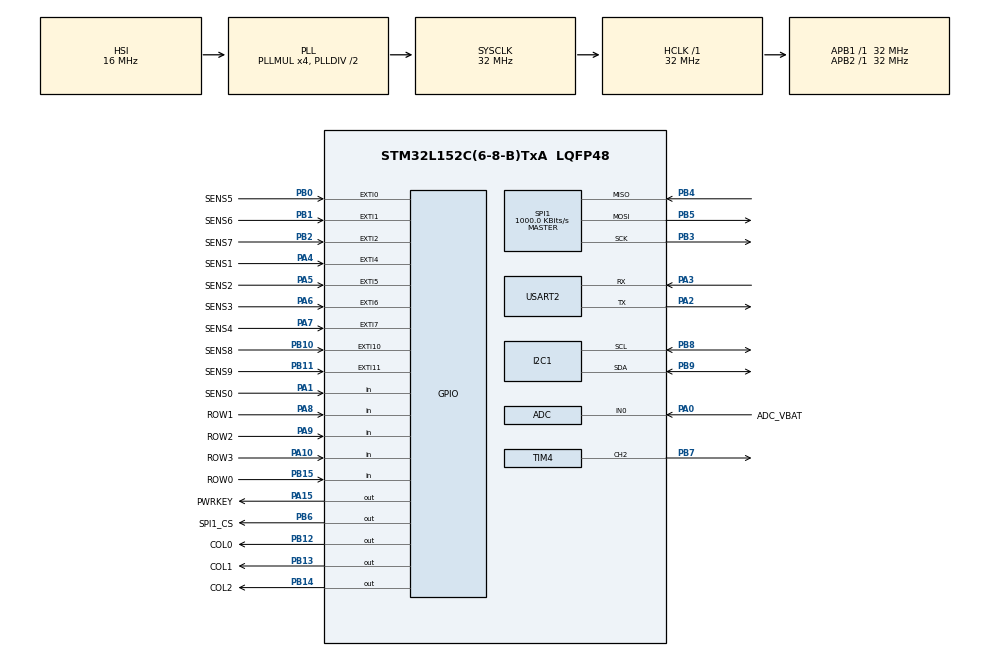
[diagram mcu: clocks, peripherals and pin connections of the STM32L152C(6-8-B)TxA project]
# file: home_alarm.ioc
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ADC.Channel-1\#ChannelRegularConversion=ADC_CHANNEL_0
ADC.NbrOfConversionFlag=1
ADC.Rank-1\#ChannelRegularConversion=1
ADC.SamplingTime-1\#ChannelRegularConversion=ADC_SAMPLETIME_4CYCLES
Dma.Request0=USART2_RX
Dma.USART2_RX.0.Direction=DMA_PERIPH_TO_MEMORY
Dma.USART2_RX.0.Instance=DMA1_Channel6
Dma.USART2_RX.0.MemDataAlignment=DMA_MDATAALIGN_BYTE
Dma.USART2_RX.0.MemInc=DMA_MINC_DISABLE
Dma.USART2_RX.0.Mode=DMA_CIRCULAR
Dma.USART2_RX.0.PeriphDataAlignment=DMA_PDATAALIGN_BYTE
Dma.USART2_RX.0.PeriphInc=DMA_PINC_DISABLE
Dma.USART2_RX.0.Priority=DMA_PRIORITY_VERY_HIGH
Mcu.Family=STM32L1
Mcu.Name=STM32L152C(6-8-B)TxA
Mcu.Package=LQFP48
NVIC.DMA1_Channel6_IRQn=true\:6\:0\:true\:false\:true\:false\:true\:true
NVIC.EXTI0_IRQn=true\:0\:0\:false\:false\:true\:true\:true\:true
NVIC.EXTI15_10_IRQn=true\:0\:0\:false\:false\:true\:true\:true\:true
NVIC.EXTI1_IRQn=true\:0\:0\:false\:false\:true\:true\:true\:true
NVIC.EXTI2_IRQn=true\:0\:0\:false\:false\:true\:true\:true\:true
NVIC.EXTI4_IRQn=true\:0\:0\:false\:false\:true\:true\:true\:true
NVIC.EXTI9_5_IRQn=true\:0\:0\:false\:false\:true\:true\:true\:true
NVIC.PriorityGroup=NVIC_PRIORITYGROUP_4
NVIC.TIM6_IRQn=true\:15\:0\:false\:false\:true\:false\:true\:true
NVIC.TimeBase=TIM6_IRQn
NVIC.TimeBaseIP=TIM6
PA0-WKUP1.GPIO_Label=ADC_VBAT
PA0-WKUP1.Mode=IN0
PA0-WKUP1.Signal=ADC_IN0
PA1.GPIO_Label=SENS0
PA1.Signal=GPIO_Input
PA10.GPIO_Label=ROW3
PA10.GPIO_PuPd=GPIO_PULLUP
PA10.Signal=GPIO_Input
PA13.Mode=Serial_Wire
PA13.Signal=SYS_JTMS-SWDIO
PA14.Mode=Serial_Wire
PA14.Signal=SYS_JTCK-SWCLK
PA15.GPIO_Label=PWRKEY
PA15.Signal=GPIO_Output
PA2.Mode=Asynchronous
PA2.Signal=USART2_TX
PA3.Mode=Asynchronous
PA3.Signal=USART2_RX
PA4.GPIO_Label=SENS1
PA4.Signal=GPXTI4
PA5.GPIO_Label=SENS2
PA5.Signal=GPXTI5
PA6.GPIO_Label=SENS3
PA6.Signal=GPXTI6
PA7.GPIO_Label=SENS4
PA7.Signal=GPXTI7
PA8.GPIO_Label=ROW1
PA8.GPIO_PuPd=GPIO_PULLUP
PA8.Signal=GPIO_Input
PA9.GPIO_Label=ROW2
PA9.GPIO_PuPd=GPIO_PULLUP
PA9.Signal=GPIO_Input
PB0.GPIO_Label=SENS5
PB0.Signal=GPXTI0
PB1.GPIO_Label=SENS6
PB1.Signal=GPXTI1
PB10.GPIO_Label=SENS8
PB10.Signal=GPXTI10
PB11.GPIO_Label=SENS9
PB11.Signal=GPXTI11
PB12.GPIO_Label=COL0
PB12.GPIO_Speed=GPIO_SPEED_FREQ_VERY_HIGH
PB12.Signal=GPIO_Output
PB13.GPIO_Label=COL1
PB13.GPIO_Speed=GPIO_SPEED_FREQ_VERY_HIGH
PB13.Signal=GPIO_Output
PB14.GPIO_Label=COL2
PB14.GPIO_Speed=GPIO_SPEED_FREQ_VERY_HIGH
PB14.Signal=GPIO_Output
PB15.GPIO_Label=ROW0
PB15.GPIO_PuPd=GPIO_PULLUP
PB15.Signal=GPIO_Input
PB2.GPIO_Label=SENS7
PB2.Signal=GPXTI2
PB3.Mode=Full_Duplex_Master
PB3.Signal=SPI1_SCK
PB4.Mode=Full_Duplex_Master
PB4.Signal=SPI1_MISO
PB5.Mode=Full_Duplex_Master
PB5.Signal=SPI1_MOSI
PB6.GPIO_Label=SPI1_CS
PB6.Signal=GPIO_Output
PB7.Signal=S_TIM4_CH2
PB8.Mode=I2C
PB8.Signal=I2C1_SCL
PB9.Mode=I2C
PB9.Signal=I2C1_SDA
ProjectManager.HeapSize=0x200
ProjectManager.StackSize=0x400
ProjectManager.TargetToolchain=STM32CubeIDE
RCC.48MHZClocksFreq_Value=32000000
RCC.AHBFreq_Value=32000000
RCC.APB1Freq_Value=32000000
RCC.APB1TimFreq_Value=32000000
RCC.APB2Freq_Value=32000000
RCC.APB2TimFreq_Value=32000000
RCC.HCLKFreq_Value=32000000
RCC.HSE_VALUE=24000000
RCC.HSI_VALUE=16000000
RCC.LSE_VALUE=32768
RCC.MSI_VALUE=2097000
RCC.PLLMUL=RCC_PLL_MUL4
RCC.SYSCLKFreq_VALUE=32000000
RCC.SYSCLKSource=RCC_SYSCLKSOURCE_PLLCLK
RCC.VCOOutputFreq_Value=64000000
SH.S_TIM4_CH2.0=TIM4_CH2,PWM Generation2 CH2
SPI1.BaudRatePrescaler=SPI_BAUDRATEPRESCALER_32
SPI1.CLKPhase=SPI_PHASE_1EDGE
SPI1.CLKPolarity=SPI_POLARITY_LOW
SPI1.CalculateBaudRate=1000.0 KBits/s
SPI1.Direction=SPI_DIRECTION_2LINES
SPI1.Mode=SPI_MODE_MASTER
SPI1.VirtualType=VM_MASTER
TIM4.AutoReloadPreload=TIM_AUTORELOAD_PRELOAD_ENABLE
TIM4.Channel-PWM\ Generation2\ CH2=TIM_CHANNEL_2
TIM4.Period=137
TIM4.Prescaler=32
USART2.VirtualMode=VM_ASYNC
VP_CRC_VS_CRC.Mode=CRC_Activate
VP_SYS_VS_tim6.Mode=TIM6
board=custom

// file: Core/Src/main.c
/* USER CODE BEGIN Header */
/**
  ******************************************************************************
  * @file           : main.c
  * @brief          : Main program body
  ******************************************************************************
  * @attention
  *
  * Copyright (c) 2022 STMicroelectronics.
  * All rights reserved.
  *
  * This software is licensed under terms that can be found in the LICENSE file
  * in the root directory of this software component.
  * If no LICENSE file comes with this software, it is provided AS-IS.
  *
  ******************************************************************************
  */
/* USER CODE END Header */
#include "main.h"
#include "adc.h"
#include "crc.h"
#include "dma.h"
#include "i2c.h"
#include "spi.h"
#include "tim.h"
#include "usart.h"
#include "gpio.h"

/* USER CODE BEGIN Includes */
#include "app.h"
/* USER CODE END Includes */

void SystemClock_Config(void);

int main(void)
{

  /* MCU Configuration--------------------------------------------------------*/

  /* Reset of all peripherals, Initializes the Flash interface and the Systick. */
  HAL_Init();

  /* Configure the system clock */
  SystemClock_Config();

  /* Initialize all configured peripherals */
  MX_GPIO_Init();
  MX_DMA_Init();
  MX_ADC_Init();
  MX_TIM4_Init();
  MX_USART2_UART_Init();
  MX_I2C1_Init();
  MX_SPI1_Init();
  MX_CRC_Init();
  /* USER CODE BEGIN 2 */
  app_main();
  /* USER CODE END 2 */

  /* Infinite loop */
  while (1)
  {

    /* USER CODE BEGIN 3 */
	  __NOP();
  }
  /* USER CODE END 3 */
}

void SystemClock_Config(void)
{
  RCC_OscInitTypeDef RCC_OscInitStruct = {0};
  RCC_ClkInitTypeDef RCC_ClkInitStruct = {0};

  /** Configure the main internal regulator output voltage
  */
  __HAL_PWR_VOLTAGESCALING_CONFIG(PWR_REGULATOR_VOLTAGE_SCALE1);

  /** Initializes the RCC Oscillators according to the specified parameters
  * in the RCC_OscInitTypeDef structure.
  */
  RCC_OscInitStruct.OscillatorType = RCC_OSCILLATORTYPE_HSI;
  RCC_OscInitStruct.HSIState = RCC_HSI_ON;
  RCC_OscInitStruct.HSICalibrationValue = RCC_HSICALIBRATION_DEFAULT;
  RCC_OscInitStruct.PLL.PLLState = RCC_PLL_ON;
  RCC_OscInitStruct.PLL.PLLSource = RCC_PLLSOURCE_HSI;
  RCC_OscInitStruct.PLL.PLLMUL = RCC_PLL_MUL4;
  RCC_OscInitStruct.PLL.PLLDIV = RCC_PLL_DIV2;
  if (HAL_RCC_OscConfig(&RCC_OscInitStruct) != HAL_OK)
  {
    Error_Handler();
  }

  /** Initializes the CPU, AHB and APB buses clocks
  */
  RCC_ClkInitStruct.ClockType = RCC_CLOCKTYPE_HCLK|RCC_CLOCKTYPE_SYSCLK
                              |RCC_CLOCKTYPE_PCLK1|RCC_CLOCKTYPE_PCLK2;
  RCC_ClkInitStruct.SYSCLKSource = RCC_SYSCLKSOURCE_PLLCLK;
  RCC_ClkInitStruct.AHBCLKDivider = RCC_SYSCLK_DIV1;
  RCC_ClkInitStruct.APB1CLKDivider = RCC_HCLK_DIV1;
  RCC_ClkInitStruct.APB2CLKDivider = RCC_HCLK_DIV1;

  if (HAL_RCC_ClockConfig(&RCC_ClkInitStruct, FLASH_LATENCY_1) != HAL_OK)
  {
    Error_Handler();
  }
}

void HAL_TIM_PeriodElapsedCallback(TIM_HandleTypeDef *htim)
{
  if (htim->Instance == TIM6) {
    HAL_IncTick();
  }
}

void Error_Handler(void)
{
  __disable_irq();
  while (1)
  {
  }
}
